# AUX_TIMER01 register map
Vendor: Texas Instruments
Peripheral module from a debugger description file (folder CC26x2x7).
Registers are 32-bit, access per field, reset 0x0 unless marked. A register's access mark holds for its fields unless they carry their own. Offsets are as the file gives them; lines under a group give offsets from that group; [hi:lo] are bit positions; {n}, {i} and the like mark numbered series; 'fields as' and 'values as' point back to an identical list; <NAME> marks a mode.

## AUX_TIMER01 — AUX Timer 0 and AUX Timer 1 (AUX_TIMER01) are two 16-bit timers capable of generating one event each: - AUX_EVCTL:EVSTAT3.AUX_TIMER0_EV. - AUX_EVCTL:EVSTAT3.AUX_TIMER1_EV. The events are described in T0TARGET and T1TARGET. Subscribers to the AUX event bus can use these events to sequence and trigger actions. AUX_SYSIF:PEROPRATE.TIMER01_OP_RATE sets the peripheral clock frequency used by the prescaler, timer, and event logic to SCE or AUX bus rate. To use AUX_TIMER01: - AUX_SCE must set AUX_SYSIF:PEROPRATE.TIMER01_OP_RATE to SCE_RATE. - System CPU must set AUX_SYSIF:PEROPRATE.TIMER01_OP_RATE to BUS_RATE. - The timers must only subscribe to events updated at the peripheral clock frequency or lower. Unexpected execution behavior can result if software does not obey these rules.
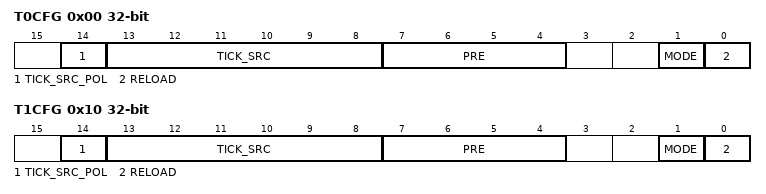
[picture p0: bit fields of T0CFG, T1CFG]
0x00 T0CFG — Timer 0 Configuration
  [14] TICK_SRC_POL rw — Tick source polarity for Timer 0.
    1=FALL (Count on falling edges of TICK_SRC.); 0=RISE (Count on rising edges of TICK_SRC.)
  [13:8] TICK_SRC rw — Select Timer 0 tick source from the synchronous event bus.
    63=AUX_TIMER2_CLKSW_RDY (AUX_EVCTL:EVSTAT3.AUX_TIMER2_CLKSWITCH_RDY); 62=AUX_DAC_HOLD_ACTIVE (AUX_EVCTL:EVSTAT3.AUX_DAC_HOLD_ACTIVE); 61=AUX_SMPH_AUTOTAKE_DONE (AUX_EVCTL:EVSTAT3.AUX_SMPH_AUTOTAKE_DONE); 60=AUX_ADC_FIFO_NOT_EMPTY (AUX_EVCTL:EVSTAT3.AUX_ADC_FIFO_NOT_EMPTY); 59=AUX_ADC_FIFO_ALMOST_FULL (AUX_EVCTL:EVSTAT3.AUX_ADC_FIFO_ALMOST_FULL); 58=AUX_ADC_IRQ (AUX_EVCTL:EVSTAT3.AUX_ADC_IRQ); 57=AUX_ADC_DONE (AUX_EVCTL:EVSTAT3.AUX_ADC_DONE); 56=AUX_ISRC_RESET_N (AUX_EVCTL:EVSTAT3.AUX_ISRC_RESET_N); 55=AUX_TDC_DONE (AUX_EVCTL:EVSTAT3.AUX_TDC_DONE); 54=NO_EVENT; 53=AUX_TIMER1_EV (AUX_EVCTL:EVSTAT3.AUX_TIMER1_EV); 52=AUX_TIMER2_PULSE (AUX_EVCTL:EVSTAT3.AUX_TIMER2_PULSE); {v}=AUX_TIMER2_EV{v-48} (AUX_EVCTL:EVSTAT3.AUX_TIMER2_EV{v-48}) (v=48..51); 47=AUX_COMPB (AUX_EVCTL:EVSTAT2.AUX_COMPB); 46=AUX_COMPA (AUX_EVCTL:EVSTAT2.AUX_COMPA); 45=MCU_OBSMUX1 (AUX_EVCTL:EVSTAT2.MCU_OBSMUX1); 44=MCU_OBSMUX0 (AUX_EVCTL:EVSTAT2.MCU_OBSMUX0); 43=MCU_EV (AUX_EVCTL:EVSTAT2.MCU_EV); 42=ACLK_REF (AUX_EVCTL:EVSTAT2.ACLK_REF); 41=VDDR_RECHARGE (AUX_EVCTL:EVSTAT2.VDDR_RECHARGE); 40=MCU_ACTIVE (AUX_EVCTL:EVSTAT2.MCU_ACTIVE); 39=PWR_DWN (AUX_EVCTL:EVSTAT2.PWR_DWN); 38=SCLK_LF (AUX_EVCTL:EVSTAT2.SCLK_LF); 37=AON_BATMON_TEMP_UPD (AUX_EVCTL:EVSTAT2.AON_BATMON_TEMP_UPD); 36=AON_BATMON_BAT_UPD (AUX_EVCTL:EVSTAT2.AON_BATMON_BAT_UPD); 35=AON_RTC_4KHZ (AUX_EVCTL:EVSTAT2.AON_RTC_4KHZ); 34=AON_RTC_CH2_DLY (AUX_EVCTL:EVSTAT2.AON_RTC_CH2_DLY); 33=AON_RTC_CH2 (AUX_EVCTL:EVSTAT2.AON_RTC_CH2); 32=MANUAL_EV (AUX_EVCTL:EVSTAT2.MANUAL_EV); {v}=AUXIO{v} (AUX_EVCTL:EVSTAT1.AUXIO{v}) (v=16..31); {v}=AUXIO{v} (AUX_EVCTL:EVSTAT0.AUXIO{v}) (v=0..15)
  [7:4] PRE rw — Prescaler division ratio is 2^PRE: 0x0: Divide by 1. 0x1: Divide by 2. 0x2: Divide by 4. ... 0xF: Divide by 32,768.
  [1] MODE rw — Timer 0 mode. Configure source for Timer 0 prescaler.
    1=TICK (Use event set by TICK_SRC as source for prescaler.); 0=CLK (Use clock as source for prescaler. Note that AUX_SYSIF:PEROPRATE.TIMER01_OP_RATE sets the clock frequency.)
  [0] RELOAD rw — Timer 0 reload mode.
    1=CONT (Continuous mode. Timer 0 restarts when the counter value becomes equal to or greater than ( T0TARGET.VALUE - 1).); 0=MAN (Manual mode. Timer 0 stops and T0CTL.EN becomes 0 when the counter value becomes equal to or greater than T0TARGET.VALUE.)
0x04 T0CTL — Timer 0 Control
  [0] EN rw — Timer 0 enable. 0: Disable Timer 0. 1: Enable Timer 0. The counter restarts from 0 when you enable Timer 0.
0x08 T0TARGET — Timer 0 Target
  [15:0] VALUE rw — Timer 0 target value. Manual Reload Mode: - Timer 0 increments until the counter value becomes equal to or greater than VALUE. - AUX_TIMER0_EV pulses high for 1 peripheral clock period when the counter value is equal to or greater than VALUE. Note: When VALUE is 0, Timer 0 counts to 1. AUX_TIMER0_EV pulses high for 1 peripheral clock period. Continuous Reload Mode: - Timer 0 increments until the counter value becomes equal to or greater than ( VALUE - 1), then restarts from 0. - AUX_TIMER0_EV pulses high for 1 peripheral clock period when the counter value is 0, except for when you enable the timer. Note: When VALUE is less than 2, Timer 0 counter value remains 0. AUX_TIMER0_EV goes high and remains high 1 peripheral clock period after you enable the timer. It is allowed to update the VALUE while the timer runs.
0x0C T0CNTR ro — Timer 0 Counter
  [15:0] VALUE — Timer 0 counter value.
0x10 T1CFG — Timer 1 Configuration
  [14] TICK_SRC_POL rw — Tick source polarity for Timer 1.
    values as T0CFG.TICK_SRC_POL
  [13:8] TICK_SRC rw — Select Timer 1 tick source from the synchronous event bus.
    63=AUX_TIMER2_CLKSW_RDY (AUX_EVCTL:EVSTAT3.AUX_TIMER2_CLKSWITCH_RDY); 62=AUX_DAC_HOLD_ACTIVE (AUX_EVCTL:EVSTAT3.AUX_DAC_HOLD_ACTIVE); 61=AUX_SMPH_AUTOTAKE_DONE (AUX_EVCTL:EVSTAT3.AUX_SMPH_AUTOTAKE_DONE); 60=AUX_ADC_FIFO_NOT_EMPTY (AUX_EVCTL:EVSTAT3.AUX_ADC_FIFO_NOT_EMPTY); 59=AUX_ADC_FIFO_ALMOST_FULL (AUX_EVCTL:EVSTAT3.AUX_ADC_FIFO_ALMOST_FULL); 58=AUX_ADC_IRQ (AUX_EVCTL:EVSTAT3.AUX_ADC_IRQ); 57=AUX_ADC_DONE (AUX_EVCTL:EVSTAT3.AUX_ADC_DONE); 56=AUX_ISRC_RESET_N (AUX_EVCTL:EVSTAT3.AUX_ISRC_RESET_N); 55=AUX_TDC_DONE (AUX_EVCTL:EVSTAT3.AUX_TDC_DONE); 54=AUX_TIMER0_EV (AUX_EVCTL:EVSTAT3.AUX_TIMER0_EV); 53=NO_EVENT; 52=AUX_TIMER2_PULSE (AUX_EVCTL:EVSTAT3.AUX_TIMER2_PULSE); {v}=AUX_TIMER2_EV{v-48} (AUX_EVCTL:EVSTAT3.AUX_TIMER2_EV{v-48}) (v=48..51); 47=AUX_COMPB (AUX_EVCTL:EVSTAT2.AUX_COMPB); 46=AUX_COMPA (AUX_EVCTL:EVSTAT2.AUX_COMPA); 45=MCU_OBSMUX1 (AUX_EVCTL:EVSTAT2.MCU_OBSMUX1); 44=MCU_OBSMUX0 (AUX_EVCTL:EVSTAT2.MCU_OBSMUX0); 43=MCU_EV (AUX_EVCTL:EVSTAT2.MCU_EV); 42=ACLK_REF (AUX_EVCTL:EVSTAT2.ACLK_REF); 41=VDDR_RECHARGE (AUX_EVCTL:EVSTAT2.VDDR_RECHARGE); 40=MCU_ACTIVE (AUX_EVCTL:EVSTAT2.MCU_ACTIVE); 39=PWR_DWN (AUX_EVCTL:EVSTAT2.PWR_DWN); 38=SCLK_LF (AUX_EVCTL:EVSTAT2.SCLK_LF); 37=AON_BATMON_TEMP_UPD (AUX_EVCTL:EVSTAT2.AON_BATMON_TEMP_UPD); 36=AON_BATMON_BAT_UPD (AUX_EVCTL:EVSTAT2.AON_BATMON_BAT_UPD); 35=AON_RTC_4KHZ (AUX_EVCTL:EVSTAT2.AON_RTC_4KHZ); 34=AON_RTC_CH2_DLY (AUX_EVCTL:EVSTAT2.AON_RTC_CH2_DLY); 33=AON_RTC_CH2 (AUX_EVCTL:EVSTAT2.AON_RTC_CH2); 32=MANUAL_EV (AUX_EVCTL:EVSTAT2.MANUAL_EV); {v}=AUXIO{v} (AUX_EVCTL:EVSTAT1.AUXIO{v}) (v=16..31); {v}=AUXIO{v} (AUX_EVCTL:EVSTAT0.AUXIO{v}) (v=0..15)
  [7:4] PRE rw — Prescaler division ratio is 2^PRE: 0x0: Divide by 1. 0x1: Divide by 2. 0x2: Divide by 4. ... 0xF: Divide by 32,768.
  [1] MODE rw — Timer 1 mode. Configure source for Timer 1 prescaler.
    values as T0CFG.MODE
  [0] RELOAD rw — Timer 1 reload mode.
    1=CONT (Continuous mode. Timer 1 restarts when the counter value becomes equal to or greater than ( T1TARGET.VALUE - 1).); 0=MAN (Manual mode. Timer 1 stops and T1CTL.EN becomes 0 when the counter value becomes equal to or greater than T1TARGET.VALUE.)
0x14 T1CTL — Timer 1 Control
  [0] EN rw — Timer 1 enable. 0: Disable Timer 1. 1: Enable Timer 1. The counter restarts from 0 when you enable Timer 1.
0x18 T1TARGET — Timer 1 Target Timer 1 counter target value
  [15:0] VALUE rw — Timer 1 target value. Manual Reload Mode: - Timer 1 increments until the counter value becomes equal to or greater than VALUE. - AUX_TIMER1_EV pulses high for 1 peripheral clock period when the counter value is equal to or greater than VALUE. Note: When VALUE is 0, Timer 1 counts to 1. AUX_TIMER1_EV pulses high for 1 peripheral clock period. Continuous Reload Mode: - Timer 1 increments until the counter value becomes equal to or greater than ( VALUE - 1), then restarts from 0. - AUX_TIMER1_EV pulses high for 1 peripheral clock period when the counter value is 0, except for when you enable the timer. Note: When VALUE is less than 2, Timer 1 counter value remains 0. AUX_TIMER1_EV goes high and remains high 1 peripheral clock period after you enable the timer. It is allowed to update the VALUE while the timer runs.
0x1C T1CNTR ro — Timer 1 Counter
  [15:0] VALUE — Timer 1 counter value.
